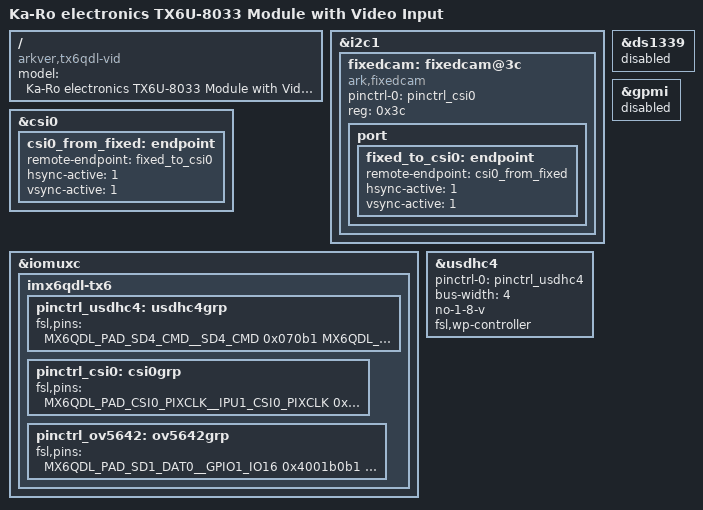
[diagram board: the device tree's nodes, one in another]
/*
 * Copyright 2016 Ian Jamison <ian.dev@arkver.com>
 *
 * The code contained herein is licensed under the GNU General Public
 * License. You may obtain a copy of the GNU General Public License
 * Version 2 at the following locations:
 *
 * http://www.opensource.org/licenses/gpl-license.html
 * http://www.gnu.org/copyleft/gpl.html
 */

/dts-v1/;
#include "imx6dl.dtsi"
#include "imx6qdl-tx6.dtsi"

/ {
	model = "Ka-Ro electronics TX6U-8033 Module with Video Input";
	compatible = "arkver,tx6qdl-vid", "karo,imx6dl-tx6dl", "fsl,imx6dl";
};

&i2c1 {
	fixedcam: fixedcam@3c {
		compatible = "ark,fixedcam";
		pinctrl-names = "default";
		pinctrl-0 = <&pinctrl_csi0>;
		reg = <0x3c>;
		
		/*
		reset-gpios = <&gpio1 8 GPIO_ACTIVE_LOW>;
		pwdn-gpios = <&gpio1 6 GPIO_ACTIVE_HIGH>;
		gp-gpios = <&gpio1 16 GPIO_ACTIVE_HIGH>;
		
		clocks = <&clks 200>;
		clock-names = "xclk";
		xclk = <24000000>;
		*/

		port {
			fixed_to_csi0: endpoint {
				remote-endpoint = <&csi0_from_fixed>;
				hsync-active = <1>;
				vsync-active = <1>;
			};
		};
	};
};

&csi0 {
	csi0_from_fixed: endpoint {
		remote-endpoint = <&fixed_to_csi0>;
		hsync-active = <1>;
		vsync-active = <1>;
	};
};

&ds1339 {
	status = "disabled";
};

&gpmi {
	status = "disabled";
};

&iomuxc {
	imx6qdl-tx6 {
		pinctrl_usdhc4: usdhc4grp {
			fsl,pins = <
				MX6QDL_PAD_SD4_CMD__SD4_CMD		0x070b1
				MX6QDL_PAD_SD4_CLK__SD4_CLK		0x070b1
				MX6QDL_PAD_SD4_DAT0__SD4_DATA0		0x070b1
				MX6QDL_PAD_SD4_DAT1__SD4_DATA1		0x070b1
				MX6QDL_PAD_SD4_DAT2__SD4_DATA2		0x070b1
				MX6QDL_PAD_SD4_DAT3__SD4_DATA3		0x070b1
				MX6QDL_PAD_NANDF_ALE__SD4_RESET		0x0b0b1
			>;
		};

		pinctrl_csi0: csi0grp {
			fsl,pins = <
				MX6QDL_PAD_CSI0_PIXCLK__IPU1_CSI0_PIXCLK	0xb0b1 /* 100KOhm PU, 100 MHz, 40 Ohm */
				MX6QDL_PAD_CSI0_DATA_EN__IPU1_CSI0_DATA_EN	0xb0b1
				MX6QDL_PAD_CSI0_MCLK__IPU1_CSI0_HSYNC		0xb0b1
				MX6QDL_PAD_CSI0_VSYNC__IPU1_CSI0_VSYNC		0xb0b1
				MX6QDL_PAD_CSI0_DAT8__IPU1_CSI0_DATA08		0xb0b1
				MX6QDL_PAD_CSI0_DAT9__IPU1_CSI0_DATA09		0xb0b1
				MX6QDL_PAD_CSI0_DAT10__IPU1_CSI0_DATA10		0xb0b1
				MX6QDL_PAD_CSI0_DAT11__IPU1_CSI0_DATA11		0xb0b1
				MX6QDL_PAD_CSI0_DAT12__IPU1_CSI0_DATA12		0xb0b1
				MX6QDL_PAD_CSI0_DAT13__IPU1_CSI0_DATA13		0xb0b1
				MX6QDL_PAD_CSI0_DAT14__IPU1_CSI0_DATA14		0xb0b1
				MX6QDL_PAD_CSI0_DAT15__IPU1_CSI0_DATA15		0xb0b1
				MX6QDL_PAD_CSI0_DAT16__IPU1_CSI0_DATA16		0xb0b1
				MX6QDL_PAD_CSI0_DAT17__IPU1_CSI0_DATA17		0xb0b1
				MX6QDL_PAD_CSI0_DAT18__IPU1_CSI0_DATA18		0xb0b1
				MX6QDL_PAD_CSI0_DAT19__IPU1_CSI0_DATA19		0xb0b1
			>;
		};

		pinctrl_ov5642: ov5642grp {
			fsl,pins = <
				MX6QDL_PAD_SD1_DAT0__GPIO1_IO16			0x4001b0b1
				MX6QDL_PAD_GPIO_6__GPIO1_IO06			0x400000b0	/* OV5642 PWDN, internal PD */
				MX6QDL_PAD_GPIO_8__GPIO1_IO08			0x400000b0	/* OV5642 RESETB, internal PU */
				MX6QDL_PAD_GPIO_3__CCM_CLKO2			0xb0b1		/* OV5642 MCLK */
			>;
		};
	};
};

&usdhc4 {
	pinctrl-names = "default";
	pinctrl-0 = <&pinctrl_usdhc4>;
	bus-width = <4>;
	no-1-8-v;
	fsl,wp-controller;
	status = "okay";
};
